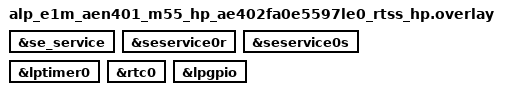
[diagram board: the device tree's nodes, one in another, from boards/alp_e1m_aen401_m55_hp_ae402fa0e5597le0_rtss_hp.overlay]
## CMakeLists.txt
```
# SPDX-License-Identifier: Apache-2.0
#
# aen-power-stop -- bench proof of the Alif SE STOP backend (#2784, unit U7) on
# the E1M-AEN803 (Alif Ensemble E8, M55-HE; the M55-HP builds too, not bench-verified).  Built as an MRAM image: STOP wakes
# through a cold boot, so the image has to be the one the Secure Enclave boots
# (a RAM-run image would not come back).
#
# Plain prj.conf app (no alp_project.py board.yaml flow); Zephyr applies
# boards/<fully-qualified-board>.overlay by itself; the overlay only enables the GPIO
# controllers of the pads the power layer drives (GPIO5, GPIO11, LPGPIO) -- BRD_I2C and
# the LPTIMER come from the board layer, and it has no ITCM retarget (MRAM image).
# Build with
#   ZEPHYR_BASE=<zephyr-base> west build \
#     -b alp_e1m_aen803_m55_he/ae822fa0e5597ls0/rtss_he <this-dir> -- \
#     "-DEXTRA_ZEPHYR_MODULES=<alp-sdk>;<hal_alif>"

cmake_minimum_required(VERSION 3.20)

find_package(Zephyr REQUIRED HINTS $ENV{ZEPHYR_BASE})
project(aen_power_stop LANGUAGES C)

# The retention-proof counter and the RV-3028 hook binding are SDK-internal (the
# portable surface is the <alp/power.h> calls this app also makes), so this bench
# app reaches the internal headers directly, like aen-power-domains.
get_filename_component(ALP_SDK_ROOT ${CMAKE_CURRENT_SOURCE_DIR}/../../.. ABSOLUTE)
target_include_directories(app PRIVATE ${ALP_SDK_ROOT}/src/backends/power)

target_sources(app PRIVATE src/main.c)
```

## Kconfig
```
# SPDX-License-Identifier: Apache-2.0
#
# Bench variants of aen-power-stop (#2784 addendum 6): one variable each, chosen with a
# config fragment (variants/<name>.conf) on top of prj.conf.

mainmenu "aen-power-stop"

config AEN_STOP_FIRST_RTC
	bool "Variant (ii): run the RV-3028 countdown cycle first"
	help
	  Cycle order becomes RV-3028 countdown, LPTIMER, RV-3028 alarm.  If the first cycle
	  wakes and the LPTIMER one does not, the RV-3028 INT path is sound and the
	  LPTIMER path is the suspect (and the reverse).

config AEN_STOP_EVI_CYCLE
	bool "Variant (E): the third cycle wakes on an RV-3028 EVI event (MODULE_STBY)"
	help
	  Replaces the alarm cycle with ALP_POWER_WAKE_EXT_EVENT (#2811).  Needs MODULE_STBY
	  (E1.O2, the RV-3028 EVI pin) driven low during the cycle: by the CC3501E GPIO18 (E1.I3)
	  joined to E1.O2 on the carrier, or by a jumper wire from MODULE_STBY (EVK header
	  P14 pin 1) to any GND.  Bench-pending.

config AEN_STOP_EVI_TIMEOUT_MS
	int "Variant (E): safety countdown behind the EVI cycle (ms)"
	default 30000
	help
	  The RV-3028 countdown armed next to EVI so an undriven pin does not park the board.
	  Must be at least 1000 (RV-3028 countdown, not the LPTIMER).  If it is what wakes the
	  SoC the cycle fails.

config AEN_STOP_LPTIMER_MS
	int "LPTIMER cycle interval (ms)"
	default 500
	help
	  Variant (iii) sets 5000 (with ALP_SDK_POWER_ALIF_SE_BENCH_LPTIMER_MAX_MS above it).

config AEN_STOP_RTC_MS
	int "RV-3028 countdown cycle length (ms)"
	default 3000
	help
	  Must stay at or above the backend's LPTIMER ceiling (1000 ms, or the bench option
	  ALP_SDK_POWER_ALIF_SE_BENCH_LPTIMER_MAX_MS) so the countdown is served by the
	  RV-3028 and not the LPTIMER.  Variant (iii) raises the ceiling and moves this to
	  11000 so that variant still changes ONE thing: the LPTIMER interval.

config AEN_STOP_MODE_STANDBY
	bool "Variant (S): sleep in ALP_POWER_MODE_STANDBY instead of STOP"
	help
	  Every cycle requests STANDBY and the verdict is mode_standby (the wake record's
	  realised_mode must read ALP_POWER_MODE_STANDBY).  STANDBY keeps the SE's own
	  always-on domain (PD2) powered on top of PD0; it is untested on silicon.

config AEN_STOP_RETAIN_TCM_KB
	int "Variant (T): TCM to retain across the sleep, KiB (0 = none)"
	range 0 256
	default 0
	help
	  Needs CONFIG_CRC=y (the variants/t-tcm-retain*.conf fragments set it); without it the
	  link fails on crc32_ieee_update.  Non-zero asks for ALP_POWER_RETAIN_TCM with this retain_kb, writes a CRC-checked
	  pattern into a 160 KiB .noinit array in the DTCM before every sleep, and checks it
	  after the wake (verdict tcm_retained).  The M55-HE DTCM is two 128 KiB retention
	  banks, so 128 asks for the first one and 256 for both.

config AEN_STOP_HP_BEACON
	bool "Variant (H): check the M55-HP kept running through each HE STOP"
	help
	  Pair with examples/aen/aen-hp-core-smoke on the M55-HP (one ATOC naming both cores).
	  After each wake, reads the HP's SRAM0 beacon (0x02000000: magic 0xA11FE000, word 3
	  counts up once per 100 ms) and passes when it counts more time than this HE boot's
	  uptime plus the sleep: the HP ran through the HE's STOP instead of booting with it.

config AEN_STOP_WAKE_TIMING
	bool "Variant (W): print the wake-to-main() timing evidence"
	depends on ALP_SDK_SOM_POWER_BKRAM_BENCH_SCRATCH
	help
	  Reads the LPRTC counter (VBAT domain, keeps running through STOP and the SE cold
	  boot; so does the RV-3028) at main() and prints it against the sleep-entry and PRE_KERNEL_1 snapshots
	  the backend keeps in BKRAM.  Needs the bench scratch option for those snapshots.

source "Kconfig.zephyr"
```

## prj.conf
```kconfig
# SPDX-License-Identifier: Apache-2.0
#
# MRAM-image config for the STOP bench on the E1M-AEN803 (M55-HE).

CONFIG_ALP_SDK=y
CONFIG_ALP_SOC_ALIF_ENSEMBLE_E8=y

# The Alif SE client the backend talks to the Secure Enclave through.
CONFIG_ARM_MHUV2=y
CONFIG_HAS_ALIF_SE_SERVICES=y

# <alp/power.h> + the SoM power-domain runtime (quiesce / restore / wake record)
# + the STOP backend itself.  The backend is EXPERIMENTAL and off by default.
CONFIG_GPIO=y
CONFIG_PINCTRL=y
CONFIG_ALP_SDK_POWER_ALIF_SE=y
# BKRAM is SDK-reserved; this adds a counter cell beside the wake record so the
# bench can prove the Utility SRAM survived STOP.  Bench images only.
CONFIG_ALP_SDK_SOM_POWER_BKRAM_BENCH_SCRATCH=y

# The short timed wake: the LPTIMER (the alp,power-wake-timer chosen node).
CONFIG_COUNTER=y

# The long timed wake and the time base: the on-module RV-3028 on BRD_I2C.
CONFIG_I2C=y
CONFIG_ALP_SDK_CHIP_RV3028C7=y

# The cache-clean loop hangs on this silicon (shared bench rule); the backend
# refuses STOP with the D-cache on.
CONFIG_DCACHE=n

CONFIG_MAIN_STACK_SIZE=4096

# Console: Alp UART console -- E1M edge UART0 (Alif UART5, P3_4/P3_5, 115200 8N1).
# After each wake the boot is cold, so the line a bench script greps is printed
# again from the start.
CONFIG_SERIAL=y
CONFIG_CONSOLE=y
CONFIG_UART_CONSOLE=y
CONFIG_UART_INTERRUPT_DRIVEN=y
CONFIG_PRINTK=y
CONFIG_LOG=n
```

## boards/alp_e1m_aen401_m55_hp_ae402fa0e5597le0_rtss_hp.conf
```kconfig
# SPDX-License-Identifier: Apache-2.0
#
# M55-HP on the E1M-AEN401 (Ensemble E4).  Built, not bench-run by Alp Lab.

# prj.conf names the E8 capability profile; the E4 HP is alif:ensemble:e4, so the
# backend's E4 registration is the one selected.
CONFIG_ALP_SOC_ALIF_ENSEMBLE_E4=y

# The boot-time clock restore (ALP_SDK_POWER_ALIF_SE_RESTORE_CLOCKS) stays off: it is
# bench-proven on the AEN803 HP only, and its PLL_CLK_SEL health check is unverified on E4.
```

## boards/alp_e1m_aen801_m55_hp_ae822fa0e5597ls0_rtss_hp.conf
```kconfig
# SPDX-License-Identifier: Apache-2.0
#
# M55-HP: UNMEASURED on the E1M-AEN801 HP (the E1M-AEN803 HP is bench-proven); kept on as
# the same SoC-level machinery, to be confirmed by a bench pass.  A STOP wake is a cold boot
# into the clock tree the Secure Enclave left (all-RC on the HE, bench U8c); re-apply the HP RUN
# profile (400 MHz, as the vendor sample does) before any peripheral init.  The Kconfig default is
# on for the HE board only, so the HP asks for it here.
CONFIG_ALP_SDK_POWER_ALIF_SE_RESTORE_CLOCKS=y
```

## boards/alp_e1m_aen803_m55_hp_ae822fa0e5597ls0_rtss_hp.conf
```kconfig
# SPDX-License-Identifier: Apache-2.0
#
# M55-HP: restore-clocks bench-proven on the E1M-AEN803 HP (2026-10-10, 400 MHz, 3/3 STOP
# cycles, HP-only and with the HE running).  A STOP wake is a cold boot into the clock tree
# the Secure Enclave left (all-RC on the HE, bench U8c); re-apply the HP RUN profile
# (400 MHz, as the vendor sample does) before any peripheral init.  The Kconfig default is
# on for the HE board only, so the HP asks for it here.
CONFIG_ALP_SDK_POWER_ALIF_SE_RESTORE_CLOCKS=y
```

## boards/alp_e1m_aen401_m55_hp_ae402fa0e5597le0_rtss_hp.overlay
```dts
/*
 * Copyright (c) 2026 Alp Lab AB
 * SPDX-License-Identifier: Apache-2.0
 *
 * aen-power-stop overlay for the E1M-AEN401 (Ensemble E4, M55-HP), MRAM image.
 * BUILT, NOT BENCH-VERIFIED on an Alp Lab bench (a customer ran 14/14 RV-3028
 * countdown wakes with se_service, lptimer0, lpgpio and rtc0 enabled, before the
 * AEN401 board had its alp,som-power node).
 *
 * The HP image must be MRAM-booted (VTOR >= 0x80000000), see the AEN803 HP overlay.
 * ensemble_e4_e6_power.dtsi declares the always-on nodes disabled; this app needs the
 * SE service channel, the LPTIMER wake, the LPRTC and the LPGPIO bank (RV-3028 INT on P15_0).
 * As on the AEN803: the SoM power layer drives the pads of every present domain, and a pad
 * whose GPIO controller is disabled makes the quiesce fail with ALP_ERR_NOT_READY; the
 * stock board tree enables GPIO5 (backlight enable) and GPIO11 (PHY reset).
 */
&se_service {
	status = "okay";
};

&seservice0r {
	status = "okay";
};

&seservice0s {
	status = "okay";
};

&lptimer0 {
	status = "okay";
};

&rtc0 {
	status = "okay";
};

&lpgpio {
	status = "okay";
};
```

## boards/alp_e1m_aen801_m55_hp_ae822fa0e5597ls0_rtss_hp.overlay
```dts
/*
 * Copyright (c) 2026 Alp Lab AB
 * SPDX-License-Identifier: Apache-2.0
 *
 * aen-power-stop overlay for the E1M-AEN801 (Ensemble E8, M55-HP), MRAM image.
 * BUILT, NOT BENCH-VERIFIED: the HE overlay beside it is the bench-proven one.
 *
 * The HP image must be MRAM-booted (VTOR >= 0x80000000): STOP wakes through a cold boot
 * and the HP has no TCM retention, so the backend refuses a TCM-booted HP image
 * (hp_vtor_not_mram).  Do NOT use the Flow C ITCM retarget for this app.
 *
 * Same pad controllers as the HE overlay: the SoM power layer drives the pads of every
 * present domain, and a pad whose GPIO controller is disabled makes the quiesce fail with
 * ALP_ERR_NOT_READY (RV-3028 INT on LPGPIO).  The stock board tree already enables
 * GPIO5 (backlight enable) and GPIO11 (PHY reset) and the LPGPIO bank; LPGPIO is
 * repeated so the overlay states everything the app needs.
 */
&lpgpio {
	status = "okay";
};

/*
 * The STOP wake timer (the alp,power-wake-timer chosen node, ALP_POWER_WAKE_TIMER)
 * is lptimer0, which the generated board tree leaves disabled (single-owner timer,
 * enabled per app, #2984).  Without this the LPTIMER cycle cannot arm.
 */
&lptimer0 {
	status = "okay";
};
```

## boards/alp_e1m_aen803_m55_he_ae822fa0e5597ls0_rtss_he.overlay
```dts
/*
 * Copyright (c) 2026 Alp Lab AB
 * SPDX-License-Identifier: Apache-2.0
 *
 * aen-power-stop overlay for the E1M-AEN803 (Ensemble E8, M55-HE), MRAM image.
 *
 * Deliberately NO ITCM retarget: this image runs from MRAM, because STOP wakes
 * through a cold boot (SES -> ATOC -> this image).
 *
 * The SoM power layer drives the pads of every present domain, and a pad whose GPIO
 * controller is disabled in the devicetree is unusable: the quiesce then fails with
 * ALP_ERR_NOT_READY and the sleep is refused (bench U8, 2026-10-09: backlight enable
 * on GPIO5, PHY reset on GPIO11).  The stock board tree enables GPIO5 and GPIO11
 * itself (the generator emits every non-LPGPIO port a present domain uses), so only
 * the LPGPIO bank (the RV-3028 alarm pad) is repeated here.
 */
&lpgpio {
	status = "okay";
};

/*
 * The STOP wake timer (the alp,power-wake-timer chosen node, ALP_POWER_WAKE_TIMER)
 * is lptimer0, which the generated board tree leaves disabled (single-owner timer,
 * enabled per app, #2984).  Without this the LPTIMER cycle cannot arm.
 */
&lptimer0 {
	status = "okay";
};
```

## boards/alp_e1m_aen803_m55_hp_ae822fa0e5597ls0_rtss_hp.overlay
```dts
/*
 * Copyright (c) 2026 Alp Lab AB
 * SPDX-License-Identifier: Apache-2.0
 *
 * aen-power-stop overlay for the E1M-AEN803 (Ensemble E8, M55-HP), MRAM image.
 * BUILT, NOT BENCH-VERIFIED: the HE overlay beside it is the bench-proven one.
 *
 * The HP image must be MRAM-booted (VTOR >= 0x80000000): STOP wakes through a cold boot
 * and the HP has no TCM retention, so the backend refuses a TCM-booted HP image
 * (hp_vtor_not_mram).  Do NOT use the Flow C ITCM retarget for this app.
 *
 * Same pad controllers as the HE overlay: the SoM power layer drives the pads of every
 * present domain, and a pad whose GPIO controller is disabled makes the quiesce fail with
 * ALP_ERR_NOT_READY (RV-3028 INT on LPGPIO).  The stock board tree already enables
 * GPIO5 (backlight enable) and GPIO11 (PHY reset) and the LPGPIO bank; LPGPIO is
 * repeated so the overlay states everything the app needs.
 */
&lpgpio {
	status = "okay";
};

/*
 * The STOP wake timer (the alp,power-wake-timer chosen node, ALP_POWER_WAKE_TIMER)
 * is lptimer0, which the generated board tree leaves disabled (single-owner timer,
 * enabled per app, #2984).  Without this the LPTIMER cycle cannot arm.
 */
&lptimer0 {
	status = "okay";
};
```

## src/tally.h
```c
/*
 * Copyright 2026 Alp Lab AB
 * SPDX-License-Identifier: Apache-2.0
 *
 * The running pass/fail totals of a STOP run, packed into ONE byte so they can ride in the same
 * retained cell as the cycle counter (see main.c).  Every STOP wake is a cold boot, so a plain
 * variable would restart at 0 on each wake and SUMMARY would only describe the last boot.
 *
 *   bits 7..3  pass total (saturates at 31)
 *   bits 2..0  fail total (saturates at 7; any non-zero value is already a failed run)
 */
#ifndef AEN_POWER_STOP_TALLY_H
#define AEN_POWER_STOP_TALLY_H

#include <stdint.h>

#define TALLY_PASS_MAX 31u
#define TALLY_FAIL_MAX 7u

static inline uint8_t tally_pack(unsigned pass, unsigned fail)
{
	if (pass > TALLY_PASS_MAX) {
		pass = TALLY_PASS_MAX;
	}
	if (fail > TALLY_FAIL_MAX) {
		fail = TALLY_FAIL_MAX;
	}
	return (uint8_t)((pass << 3) | fail);
}

static inline void tally_unpack(uint8_t t, unsigned *pass, unsigned *fail)
{
	*pass = t >> 3;
	*fail = t & TALLY_FAIL_MAX;
}

#endif /* AEN_POWER_STOP_TALLY_H */
```
